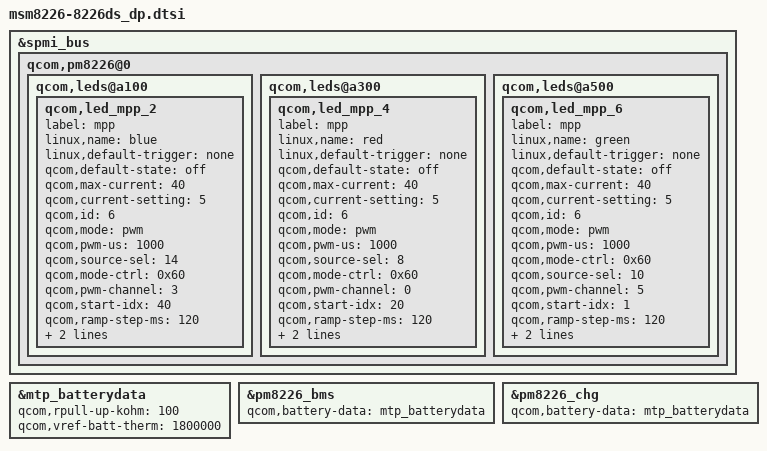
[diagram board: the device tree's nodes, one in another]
/include/ "msm8226-8226ds_pdp2.dtsi"

/* [Arima5908][33547][JessicaTseng] [All][Main][LED][DMS]Modify LED configure for DP HW 20140204 start */
&spmi_bus {
	qcom,pm8226@0 {
		qcom,leds@a100 {
			status = "okay";
			qcom,led_mpp_2 {
				label = "mpp";
				linux,name = "blue";
				linux,default-trigger = "none";
				qcom,default-state = "off";
				qcom,max-current = <40>;
				qcom,current-setting = <5>;
				qcom,id = <6>;
				qcom,mode = "pwm";
				qcom,pwm-us = <1000>;
				qcom,source-sel = <14>;
				qcom,mode-ctrl = <0x60>;
				qcom,pwm-channel = <3>;
				qcom,start-idx = <40>;
				qcom,ramp-step-ms = <120>;
				qcom,duty-pcts = [00 00 50 99 99 99 50 00];
				qcom,use-blink;
			};
		};

		qcom,leds@a300 {
			status = "okay";
			qcom,led_mpp_4 {
				label = "mpp";
				linux,name = "red";
				linux,default-trigger = "none";
				qcom,default-state = "off";
				qcom,max-current = <40>;
				qcom,current-setting = <5>;
				qcom,id = <6>;
				qcom,mode = "pwm";
				qcom,pwm-us = <1000>;
				qcom,source-sel = <8>;
				qcom,mode-ctrl = <0x60>;
				qcom,pwm-channel = <0>;
				qcom,start-idx = <20>;
				qcom,ramp-step-ms = <120>;
				qcom,duty-pcts = [00 00 50 99 99 99 50 00];
				qcom,use-blink;
			};
		};

		qcom,leds@a500 {
			status = "okay";
			qcom,led_mpp_6 {
				label = "mpp";
				linux,name = "green";
				linux,default-trigger = "none";
				qcom,default-state = "off";
				qcom,max-current = <40>;
				qcom,current-setting = <5>;
				qcom,id = <6>;
				qcom,mode = "pwm";
				qcom,pwm-us = <1000>;
				qcom,mode-ctrl = <0x60>;
				qcom,source-sel = <10>;
				qcom,pwm-channel = <5>;
				qcom,start-idx = <1>;
				qcom,ramp-step-ms = <120>;
				qcom,duty-pcts = [00 00 50 99 99 99 50 00];
				qcom,use-blink;
			};
		};
	};
};
/* [Arima5908][33547][JessicaTseng] [All][Main][LED][DMS]Modify LED configure for DP HW 20140204 end */

/*[Arima5911][35440][bozhi_lin] apply Lucisus2_1458334_2330mAh battery data from QCT 20140328 begin*/
&mtp_batterydata{
	qcom,rpull-up-kohm = <100>;
	qcom,vref-batt-therm = <1800000>;
	/include/ "batterydata-8226ds_dp.dtsi"
};

&pm8226_bms {
	qcom,battery-data = <&mtp_batterydata>;
};

&pm8226_chg {
	qcom,battery-data = <&mtp_batterydata>;
};
/*[Arima5911][35440][bozhi_lin] 20140328 end  */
